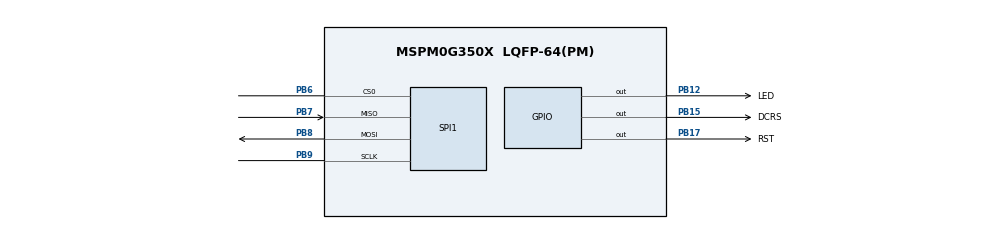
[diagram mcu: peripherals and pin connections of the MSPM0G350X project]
/**
 * @cliArgs --device "MSPM0G350X" --package "LQFP-64(PM)" --part "Default" --product "mspm0_sdk@2.01.00.03"
 * @versions {"tool":"1.20.0+3587"}
 */

/**
 * Import the modules used in this configuration.
 */
const DMA    = scripting.addModule("/ti/driverlib/DMA");
const GPIO   = scripting.addModule("/ti/driverlib/GPIO", {}, false);
const GPIO1  = GPIO.addInstance();
const GPIO2  = GPIO.addInstance();
const SPI    = scripting.addModule("/ti/driverlib/SPI", {}, false);
const SPI1   = SPI.addInstance();
const SYSCTL = scripting.addModule("/ti/driverlib/SYSCTL");
const TIMER  = scripting.addModule("/ti/driverlib/TIMER", {}, false);
const TIMER1 = TIMER.addInstance();

/**
 * Write custom configuration values to the imported modules.
 */
const Board = scripting.addModule("/ti/driverlib/Board", {}, false);

GPIO1.$name                          = "GPIO_LED";
GPIO1.associatedPins[0].$name        = "PA0_Alive";
GPIO1.associatedPins[0].assignedPort = "PORTA";
GPIO1.associatedPins[0].assignedPin  = "0";

GPIO2.$name                          = "GPIO_LCD";
GPIO2.associatedPins.create(3);
GPIO2.associatedPins[0].$name        = "LED";
GPIO2.associatedPins[0].assignedPort = "PORTB";
GPIO2.associatedPins[0].pin.$assign  = "PB12";
GPIO2.associatedPins[1].$name        = "DCRS";
GPIO2.associatedPins[1].assignedPort = "PORTB";
GPIO2.associatedPins[1].pin.$assign  = "PB15";
GPIO2.associatedPins[2].$name        = "RST";
GPIO2.associatedPins[2].assignedPort = "PORTB";
GPIO2.associatedPins[2].pin.$assign  = "PB17";

SPI1.$name                                 = "SPI_0_lcd";
SPI1.rxFifoThreshold                       = "DL_SPI_RX_FIFO_LEVEL_ONE_FRAME";
SPI1.txFifoThreshold                       = "DL_SPI_TX_FIFO_LEVEL_ONE_FRAME";
SPI1.enabledDMAEvent2Triggers              = "DL_SPI_DMA_INTERRUPT_TX";
SPI1.peripheral.$assign                    = "SPI1";
SPI1.peripheral.sclkPin.$assign            = "PB9";
SPI1.peripheral.mosiPin.$assign            = "PB8";
SPI1.peripheral.misoPin.$assign            = "PB7";
SPI1.peripheral.cs0Pin.$assign             = "PB6";
SPI1.sclkPinConfig.$name                   = "ti_driverlib_gpio_GPIOPinGeneric0";
SPI1.sclkPinConfig.direction               = scripting.forceWrite("OUTPUT");
SPI1.sclkPinConfig.onlyInternalResistor    = scripting.forceWrite(false);
SPI1.sclkPinConfig.passedPeripheralType    = scripting.forceWrite("Digital");
SPI1.mosiPinConfig.$name                   = "ti_driverlib_gpio_GPIOPinGeneric1";
SPI1.mosiPinConfig.direction               = scripting.forceWrite("OUTPUT");
SPI1.mosiPinConfig.hideOutputInversion     = scripting.forceWrite(false);
SPI1.mosiPinConfig.onlyInternalResistor    = scripting.forceWrite(false);
SPI1.mosiPinConfig.passedPeripheralType    = scripting.forceWrite("Digital");
SPI1.misoPinConfig.$name                   = "ti_driverlib_gpio_GPIOPinGeneric2";
SPI1.misoPinConfig.onlyInternalResistor    = scripting.forceWrite(false);
SPI1.misoPinConfig.passedPeripheralType    = scripting.forceWrite("Digital");
SPI1.cs0PinConfig.$name                    = "ti_driverlib_gpio_GPIOPinGeneric3";
SPI1.cs0PinConfig.direction                = scripting.forceWrite("OUTPUT");
SPI1.cs0PinConfig.hideOutputInversion      = scripting.forceWrite(false);
SPI1.cs0PinConfig.onlyInternalResistor     = scripting.forceWrite(false);
SPI1.cs0PinConfig.passedPeripheralType     = scripting.forceWrite("Digital");
SPI1.DMA_CHANNEL_EVENT2.$name              = "DMA_CH0";
SPI1.DMA_CHANNEL_EVENT2.srcLength          = "BYTE";
SPI1.DMA_CHANNEL_EVENT2.dstLength          = "BYTE";
SPI1.DMA_CHANNEL_EVENT2.addressMode        = "f2b";
SPI1.DMA_CHANNEL_EVENT2.peripheral.$assign = "DMA_CH0";

SYSCTL.forceDefaultClkConfig = true;

TIMER1.$name              = "TIMERG0_Alive";
TIMER1.timerClkSrc        = "LFCLK";
TIMER1.timerClkPrescale   = 32;
TIMER1.timerPeriod        = "500 ms";
TIMER1.timerMode          = "PERIODIC";
TIMER1.interrupts         = ["ZERO"];
TIMER1.peripheral.$assign = "TIMG0";

/**
 * Pinmux solution for unlocked pins/peripherals. This ensures that minor changes to the automatic solver in a future
 * version of the tool will not impact the pinmux you originally saw.  These lines can be completely deleted in order to
 * re-solve from scratch.
 */
Board.peripheral.$suggestSolution            = "DEBUGSS";
Board.peripheral.swclkPin.$suggestSolution   = "PA20";
Board.peripheral.swdioPin.$suggestSolution   = "PA19";
GPIO1.associatedPins[0].pin.$suggestSolution = "PA0";
SYSCTL.peripheral.$suggestSolution           = "SYSCTL";
